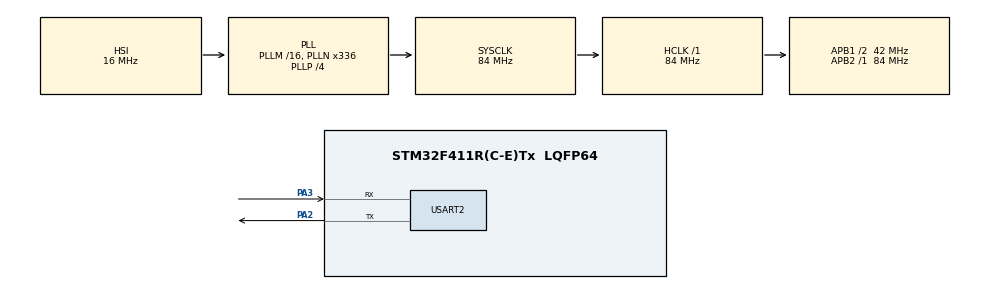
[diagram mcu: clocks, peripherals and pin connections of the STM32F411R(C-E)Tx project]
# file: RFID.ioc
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Mcu.Family=STM32F4
Mcu.Name=STM32F411R(C-E)Tx
Mcu.Package=LQFP64
NVIC.PriorityGroup=NVIC_PRIORITYGROUP_0
PA2.Mode=Asynchronous
PA2.Signal=USART2_TX
PA3.Mode=Asynchronous
PA3.Signal=USART2_RX
ProjectManager.HeapSize=0x200
ProjectManager.StackSize=0x400
ProjectManager.TargetToolchain=STM32CubeIDE
RCC.48MHZClocksFreq_Value=84000000
RCC.AHBFreq_Value=84000000
RCC.APB1CLKDivider=RCC_HCLK_DIV2
RCC.APB1Freq_Value=42000000
RCC.APB1TimFreq_Value=84000000
RCC.APB2Freq_Value=84000000
RCC.APB2TimFreq_Value=84000000
RCC.CortexFreq_Value=84000000
RCC.FLatency-AdvancedSettings=FLASH_LATENCY_2
RCC.HCLKFreq_Value=84000000
RCC.HSE_VALUE=8000000
RCC.HSI_VALUE=16000000
RCC.PLLN=336
RCC.PLLP=RCC_PLLP_DIV4
RCC.SYSCLKFreq_VALUE=84000000
RCC.SYSCLKSource=RCC_SYSCLKSOURCE_PLLCLK
RCC.VCOOutputFreq_Value=336000000
USART2.VirtualMode=VM_ASYNC
board=NUCLEO-F411RE

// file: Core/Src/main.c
/* USER CODE BEGIN Header */
/**
  ******************************************************************************
  * @file           : main.c
  * @brief          : EM-18 RFID Reader with STM32F411RE
  ******************************************************************************
  */
/* USER CODE END Header */

#include "main.h"
#include <string.h>  // For string handling

UART_HandleTypeDef huart2;

uint8_t rxBuffer[12]; // EM-18 RFID sends 12 characters including '\r' and '\n'

void SystemClock_Config(void);
static void MX_GPIO_Init(void);
static void MX_USART2_UART_Init(void);

/* USER CODE BEGIN 0 */
// Function to print data to UART (Putty)
void UART_Print(char *str)
{
    HAL_UART_Transmit(&huart2, (uint8_t *)str, strlen(str), HAL_MAX_DELAY);
}
/* USER CODE END 0 */

int main(void)
{
  HAL_Init();
  SystemClock_Config();
  MX_GPIO_Init();
  MX_USART2_UART_Init();

  UART_Print("RFID Reader Initialized\r\n");

  while (1)
  {
    // Read 12 characters from EM-18
    HAL_UART_Receive(&huart2, rxBuffer, 12, HAL_MAX_DELAY);

    // Print the received tag number
    UART_Print("Tag Detected: ");
    UART_Print((char*)rxBuffer);
    UART_Print("\r\n");

    HAL_Delay(1000);  // Small delay for stability
  }
}

void SystemClock_Config(void)
{
  RCC_OscInitTypeDef RCC_OscInitStruct = {0};
  RCC_ClkInitTypeDef RCC_ClkInitStruct = {0};

  __HAL_RCC_PWR_CLK_ENABLE();
  __HAL_PWR_VOLTAGESCALING_CONFIG(PWR_REGULATOR_VOLTAGE_SCALE1);

  RCC_OscInitStruct.OscillatorType = RCC_OSCILLATORTYPE_HSI;
  RCC_OscInitStruct.HSIState = RCC_HSI_ON;
  RCC_OscInitStruct.HSICalibrationValue = RCC_HSICALIBRATION_DEFAULT;
  RCC_OscInitStruct.PLL.PLLState = RCC_PLL_ON;
  RCC_OscInitStruct.PLL.PLLSource = RCC_PLLSOURCE_HSI;
  RCC_OscInitStruct.PLL.PLLM = 16;
  RCC_OscInitStruct.PLL.PLLN = 336;
  RCC_OscInitStruct.PLL.PLLP = RCC_PLLP_DIV4;
  RCC_OscInitStruct.PLL.PLLQ = 4;
  if (HAL_RCC_OscConfig(&RCC_OscInitStruct) != HAL_OK)
  {
    Error_Handler();
  }

  RCC_ClkInitStruct.ClockType = RCC_CLOCKTYPE_HCLK|RCC_CLOCKTYPE_SYSCLK
                              |RCC_CLOCKTYPE_PCLK1|RCC_CLOCKTYPE_PCLK2;
  RCC_ClkInitStruct.SYSCLKSource = RCC_SYSCLKSOURCE_PLLCLK;
  RCC_ClkInitStruct.AHBCLKDivider = RCC_SYSCLK_DIV1;
  RCC_ClkInitStruct.APB1CLKDivider = RCC_HCLK_DIV2;
  RCC_ClkInitStruct.APB2CLKDivider = RCC_HCLK_DIV1;

  if (HAL_RCC_ClockConfig(&RCC_ClkInitStruct, FLASH_LATENCY_2) != HAL_OK)
  {
    Error_Handler();
  }
}

static void MX_USART2_UART_Init(void)
{
  huart2.Instance = USART2;
  huart2.Init.BaudRate = 9600; // EM-18 RFID uses 9600 baud rate
  huart2.Init.WordLength = UART_WORDLENGTH_8B;
  huart2.Init.StopBits = UART_STOPBITS_1;
  huart2.Init.Parity = UART_PARITY_NONE;
  huart2.Init.Mode = UART_MODE_TX_RX;
  huart2.Init.HwFlowCtl = UART_HWCONTROL_NONE;
  huart2.Init.OverSampling = UART_OVERSAMPLING_16;
  if (HAL_UART_Init(&huart2) != HAL_OK)
  {
    Error_Handler();
  }
}

static void MX_GPIO_Init(void)
{
  __HAL_RCC_GPIOA_CLK_ENABLE();
}

/**
  * @brief  Error Handler
  */
void Error_Handler(void)
{
  __disable_irq();
  while (1) {}
}
